VERSION ""

NS_ :

BS_:

BU_: AMS RES MCU DBU SWU ECU CCU DCU VMUF VMUR EBS IMU XBB CTMD DL

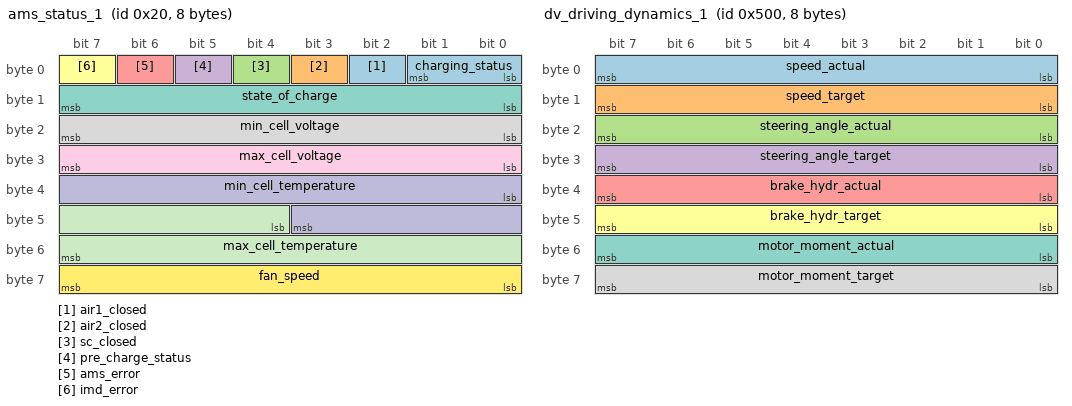
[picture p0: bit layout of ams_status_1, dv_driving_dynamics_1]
BO_ 32 ams_status_1: 8 AMS
 SG_ air1_closed : 2|1@1+ (1,0) [0|0] "" Vector__XXX
 SG_ air2_closed : 3|1@1+ (1,0) [0|0] "" Vector__XXX
 SG_ sc_closed : 4|1@1+ (1,0) [0|0] "" Vector__XXX
 SG_ pre_charge_status : 5|1@1+ (1,0) [0|0] "" Vector__XXX
 SG_ ams_error : 6|1@1+ (1,0) [0|0] "" Vector__XXX
 SG_ imd_error : 7|1@1+ (1,0) [0|0] "" Vector__XXX
 SG_ state_of_charge : 8|8@1+ (1,0) [0|100] "%" Vector__XXX
 SG_ min_cell_voltage : 16|8@1+ (0.00784,2.5) [2.5|4.5] "V" Vector__XXX
 SG_ max_cell_voltage : 24|8@1+ (0.00784,2.5) [2.5|4.5] "V" Vector__XXX
 SG_ min_cell_temperature : 32|12@1- (0.04884,-10) [-10|190] "C" Vector__XXX
 SG_ max_cell_temperature : 44|12@1- (0.04884,-10) [-10|190] "C" Vector__XXX
 SG_ fan_speed : 56|8@1+ (1,0) [0|100] "%" Vector__XXX
 SG_ charging_status : 0|2@1+ (1,0) [0|0] "" Vector__XXX

BO_ 1280 dv_driving_dynamics_1: 8 MCU
 SG_ speed_actual : 0|8@1+ (1,0) [0|0] "kmh" Vector__XXX
 SG_ speed_target : 8|8@1+ (1,0) [0|0] "kmh" Vector__XXX
 SG_ steering_angle_actual : 16|8@1- (0.5,0) [0|0] "degree" Vector__XXX
 SG_ steering_angle_target : 24|8@1- (0.5,0) [0|0] "degree" Vector__XXX
 SG_ brake_hydr_actual : 32|8@1+ (1,0) [0|0] "%" Vector__XXX
 SG_ brake_hydr_target : 40|8@1+ (1,0) [0|0] "%" Vector__XXX
 SG_ motor_moment_actual : 48|8@1- (1,0) [0|0] "%" Vector__XXX
 SG_ motor_moment_target : 56|8@1- (1,0) [0|0] "%" Vector__XXX

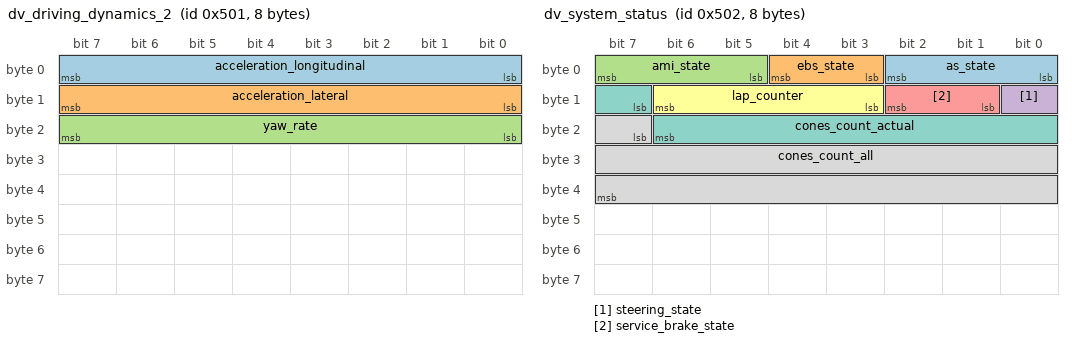
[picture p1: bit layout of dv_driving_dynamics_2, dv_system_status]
BO_ 1281 dv_driving_dynamics_2: 8 MCU
 SG_ acceleration_longitudinal : 0|8@1- (0.001953125,0) [0|0] "mps2" Vector__XXX
 SG_ acceleration_lateral : 8|8@1- (0.001953125,0) [0|0] "mps2" Vector__XXX
 SG_ yaw_rate : 16|8@1- (0.00195312,0) [0|0] "degree/s" Vector__XXX

BO_ 1282 dv_system_status: 8 MCU
 SG_ as_state : 0|3@1+ (1,0) [0|0] "" Vector__XXX
 SG_ ebs_state : 3|2@1+ (1,0) [0|0] "" Vector__XXX
 SG_ ami_state : 5|3@1+ (1,0) [0|0] "" Vector__XXX
 SG_ steering_state : 8|1@1+ (1,0) [0|0] "" Vector__XXX
 SG_ service_brake_state : 9|2@1+ (1,0) [0|0] "" Vector__XXX
 SG_ lap_counter : 11|4@1+ (1,0) [0|0] "" Vector__XXX
 SG_ cones_count_actual : 15|8@1+ (1,0) [0|0] "" Vector__XXX
 SG_ cones_count_all : 23|17@1+ (1,0) [0|0] "" Vector__XXX

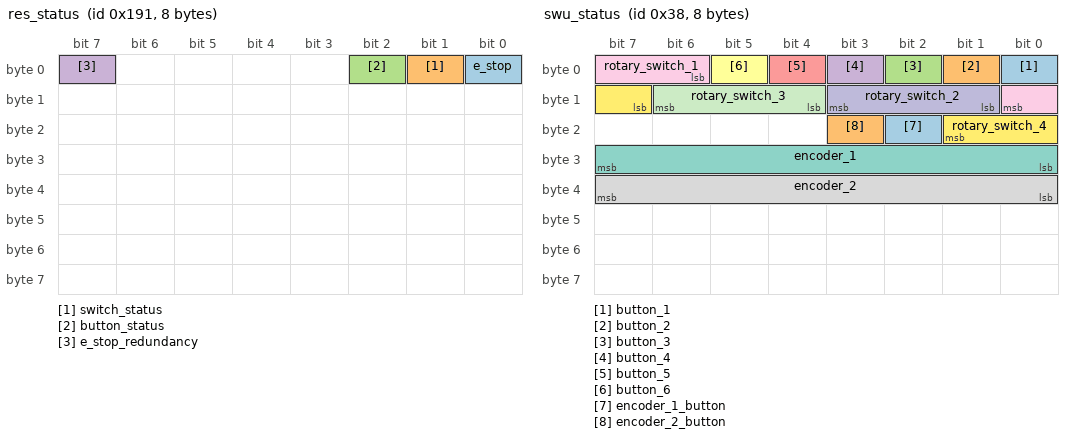
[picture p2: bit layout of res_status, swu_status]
BO_ 401 res_status: 8 RES
 SG_ e_stop : 0|1@1+ (1,0) [0|0] "" Vector__XXX
 SG_ switch_status : 1|1@1+ (1,0) [0|0] "" Vector__XXX
 SG_ button_status : 2|1@1+ (1,0) [0|0] "" Vector__XXX
 SG_ e_stop_redundancy : 7|1@1+ (1,0) [0|0] "" Vector__XXX

BO_ 1809 res_initialization: 8 MCU
 SG_ res_init : 0|8@1+ (1,0) [0|0] "" Vector__XXX

BO_ 0 res_ntm_node_control: 8 MCU
 SG_ requested_state : 0|8@1+ (1,0) [0|0] "" Vector__XXX
 SG_ node_id : 8|8@1+ (1,0) [0|0] "" Vector__XXX

BO_ 56 swu_status: 8 SWU
 SG_ button_1 : 0|1@1+ (1,0) [0|0] "" Vector__XXX
 SG_ button_2 : 1|1@1+ (1,0) [0|0] "" Vector__XXX
 SG_ button_3 : 2|1@1+ (1,0) [0|0] "" Vector__XXX
 SG_ button_4 : 3|1@1+ (1,0) [0|0] "" Vector__XXX
 SG_ button_5 : 4|1@1+ (1,0) [0|0] "" Vector__XXX
 SG_ button_6 : 5|1@1+ (1,0) [0|0] "" Vector__XXX
 SG_ encoder_1 : 24|8@1- (1,0) [-128|127] "" Vector__XXX
 SG_ encoder_2 : 32|8@1- (1,0) [-128|127] "" Vector__XXX
 SG_ rotary_switch_1 : 6|3@1+ (1,0) [0|7] "" Vector__XXX
 SG_ rotary_switch_2 : 9|3@1+ (1,0) [0|7] "" Vector__XXX
 SG_ rotary_switch_3 : 12|3@1+ (1,0) [0|7] "" Vector__XXX
 SG_ rotary_switch_4 : 15|3@1+ (1,0) [0|7] "" Vector__XXX
 SG_ encoder_1_button : 18|1@1+ (1,0) [0|0] "" Vector__XXX
 SG_ encoder_2_button : 19|1@1+ (1,0) [0|0] "" Vector__XXX

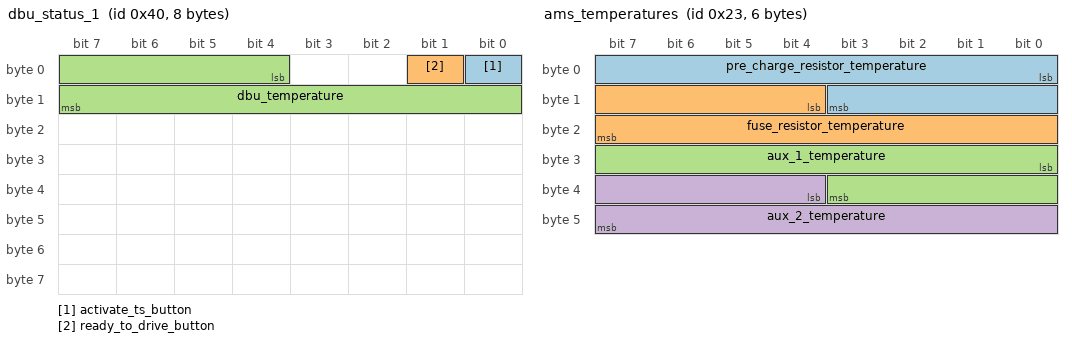
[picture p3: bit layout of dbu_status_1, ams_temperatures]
BO_ 64 dbu_status_1: 8 DBU
 SG_ activate_ts_button : 0|1@1+ (1,0) [0|0] "" AMS
 SG_ ready_to_drive_button : 1|1@1+ (1,0) [0|0] "" CCU
 SG_ dbu_temperature : 4|12@1- (0.04884,-10) [-10|190] "C" Vector__XXX

BO_ 35 ams_temperatures: 6 AMS
 SG_ pre_charge_resistor_temperature : 0|12@1- (0.04884,-10) [-10|190] "C" Vector__XXX
 SG_ fuse_resistor_temperature : 12|12@1- (0.04884,-10) [-10|190] "C" Vector__XXX
 SG_ aux_1_temperature : 24|12@1- (0.04884,-10) [-10|190] "C" Vector__XXX
 SG_ aux_2_temperature : 36|12@1- (0.04884,-10) [-10|190] "C" Vector__XXX

BO_ 33 ams_cell_voltages: 7 AMS
 SG_ voltage_multiplexor M : 0|8@1+ (1,0) [0|0] "" Vector__XXX
 SG_ v1s1 m0 : 8|8@1+ (0.00784,2.5) [2.5|4.5] "V" Vector__XXX
 SG_ v2s1 m0 : 16|8@1+ (0.00784,2.5) [2.5|4.5] "V" Vector__XXX
 SG_ v3s1 m0 : 24|8@1+ (0.00784,2.5) [2.5|4.5] "V" Vector__XXX
 SG_ v4s1 m0 : 32|8@1+ (0.00784,2.5) [2.5|4.5] "V" Vector__XXX
 SG_ v5s1 m0 : 40|8@1+ (0.00784,2.5) [2.5|4.5] "V" Vector__XXX
 SG_ v6s1 m0 : 48|8@1+ (0.00784,2.5) [2.5|4.5] "V" Vector__XXX
 SG_ v7s1 m1 : 8|8@1+ (0.00784,2.5) [2.5|4.5] "V" Vector__XXX
 SG_ v8s1 m1 : 16|8@1+ (0.00784,2.5) [2.5|4.5] "V" Vector__XXX
 SG_ v9s1 m1 : 24|8@1+ (0.00784,2.5) [2.5|4.5] "V" Vector__XXX
 SG_ v10s1 m1 : 32|8@1+ (0.00784,2.5) [2.5|4.5] "V" Vector__XXX
 SG_ v11s1 m1 : 40|8@1+ (0.00784,2.5) [2.5|4.5] "V" Vector__XXX
 SG_ v1s2 m2 : 8|8@1+ (0.00784,2.5) [2.5|4.5] "V" Vector__XXX
 SG_ v2s2 m2 : 16|8@1+ (0.00784,2.5) [2.5|4.5] "V" Vector__XXX
 SG_ v3s2 m2 : 24|8@1+ (0.00784,2.5) [2.5|4.5] "V" Vector__XXX
 SG_ v4s2 m2 : 32|8@1+ (0.00784,2.5) [2.5|4.5] "V" Vector__XXX
 SG_ v5s2 m2 : 40|8@1+ (0.00784,2.5) [2.5|4.5] "V" Vector__XXX
 SG_ v6s2 m2 : 48|8@1+ (0.00784,2.5) [2.5|4.5] "V" Vector__XXX
 SG_ v7s2 m3 : 8|8@1+ (0.00784,2.5) [2.5|4.5] "V" Vector__XXX
 SG_ v8s2 m3 : 16|8@1+ (0.00784,2.5) [2.5|4.5] "V" Vector__XXX
 SG_ v9s2 m3 : 24|8@1+ (0.00784,2.5) [2.5|4.5] "V" Vector__XXX
 SG_ v10s2 m3 : 32|8@1+ (0.00784,2.5) [2.5|4.5] "V" Vector__XXX
 SG_ v1s3 m4 : 8|8@1+ (0.00784,2.5) [2.5|4.5] "V" Vector__XXX
 SG_ v2s3 m4 : 16|8@1+ (0.00784,2.5) [2.5|4.5] "V" Vector__XXX
 SG_ v3s3 m4 : 24|8@1+ (0.00784,2.5) [2.5|4.5] "V" Vector__XXX
 SG_ v4s3 m4 : 32|8@1+ (0.00784,2.5) [2.5|4.5] "V" Vector__XXX
 SG_ v5s3 m4 : 40|8@1+ (0.00784,2.5) [2.5|4.5] "V" Vector__XXX
 SG_ v6s3 m4 : 48|8@1+ (0.00784,2.5) [2.5|4.5] "V" Vector__XXX
 SG_ v7s3 m5 : 8|8@1+ (0.00784,2.5) [2.5|4.5] "V" Vector__XXX
 SG_ v8s3 m5 : 16|8@1+ (0.00784,2.5) [2.5|4.5] "V" Vector__XXX
 SG_ v9s3 m5 : 24|8@1+ (0.00784,2.5) [2.5|4.5] "V" Vector__XXX
 SG_ v10s3 m5 : 32|8@1+ (0.00784,2.5) [2.5|4.5] "V" Vector__XXX
 SG_ v11s3 m5 : 40|8@1+ (0.00784,2.5) [2.5|4.5] "V" Vector__XXX
 SG_ v1s4 m6 : 8|8@1+ (0.00784,2.5) [2.5|4.5] "V" Vector__XXX
 SG_ v2s4 m6 : 16|8@1+ (0.00784,2.5) [2.5|4.5] "V" Vector__XXX
 SG_ v3s4 m6 : 24|8@1+ (0.00784,2.5) [2.5|4.5] "V" Vector__XXX
 SG_ v4s4 m6 : 32|8@1+ (0.00784,2.5) [2.5|4.5] "V" Vector__XXX
 SG_ v5s4 m6 : 40|8@1+ (0.00784,2.5) [2.5|4.5] "V" Vector__XXX
 SG_ v6s4 m6 : 48|8@1+ (0.00784,2.5) [2.5|4.5] "V" Vector__XXX
 SG_ v7s4 m7 : 8|8@1+ (0.00784,2.5) [2.5|4.5] "V" Vector__XXX
 SG_ v8s4 m7 : 16|8@1+ (0.00784,2.5) [2.5|4.5] "V" Vector__XXX
 SG_ v9s4 m7 : 24|8@1+ (0.00784,2.5) [2.5|4.5] "V" Vector__XXX
 SG_ v10s4 m7 : 32|8@1+ (0.00784,2.5) [2.5|4.5] "V" Vector__XXX
 SG_ v1s5 m8 : 8|8@1+ (0.00784,2.5) [2.5|4.5] "V" Vector__XXX
 SG_ v2s5 m8 : 16|8@1+ (0.00784,2.5) [2.5|4.5] "V" Vector__XXX
 SG_ v3s5 m8 : 24|8@1+ (0.00784,2.5) [2.5|4.5] "V" Vector__XXX
 SG_ v4s5 m8 : 32|8@1+ (0.00784,2.5) [2.5|4.5] "V" Vector__XXX
 SG_ v5s5 m8 : 40|8@1+ (0.00784,2.5) [2.5|4.5] "V" Vector__XXX
 SG_ v6s5 m8 : 48|8@1+ (0.00784,2.5) [2.5|4.5] "V" Vector__XXX
 SG_ v7s5 m9 : 8|8@1+ (0.00784,2.5) [2.5|4.5] "V" Vector__XXX
 SG_ v8s5 m9 : 16|8@1+ (0.00784,2.5) [2.5|4.5] "V" Vector__XXX
 SG_ v9s5 m9 : 24|8@1+ (0.00784,2.5) [2.5|4.5] "V" Vector__XXX
 SG_ v10s5 m9 : 32|8@1+ (0.00784,2.5) [2.5|4.5] "V" Vector__XXX
 SG_ v11s5 m9 : 40|8@1+ (0.00784,2.5) [2.5|4.5] "V" Vector__XXX
 SG_ v1s6 m10 : 8|8@1+ (0.00784,2.5) [2.5|4.5] "V" Vector__XXX
 SG_ v2s6 m10 : 16|8@1+ (0.00784,2.5) [2.5|4.5] "V" Vector__XXX
 SG_ v3s6 m10 : 24|8@1+ (0.00784,2.5) [2.5|4.5] "V" Vector__XXX
 SG_ v4s6 m10 : 32|8@1+ (0.00784,2.5) [2.5|4.5] "V" Vector__XXX
 SG_ v5s6 m10 : 40|8@1+ (0.00784,2.5) [2.5|4.5] "V" Vector__XXX
 SG_ v6s6 m10 : 48|8@1+ (0.00784,2.5) [2.5|4.5] "V" Vector__XXX
 SG_ v7s6 m11 : 8|8@1+ (0.00784,2.5) [2.5|4.5] "V" Vector__XXX
 SG_ v8s6 m11 : 16|8@1+ (0.00784,2.5) [2.5|4.5] "V" Vector__XXX
 SG_ v9s6 m11 : 24|8@1+ (0.00784,2.5) [2.5|4.5] "V" Vector__XXX
 SG_ v10s6 m11 : 32|8@1+ (0.00784,2.5) [2.5|4.5] "V" Vector__XXX
 SG_ v1s7 m12 : 8|8@1+ (0.00784,2.5) [2.5|4.5] "V" Vector__XXX
 SG_ v2s7 m12 : 16|8@1+ (0.00784,2.5) [2.5|4.5] "V" Vector__XXX
 SG_ v3s7 m12 : 24|8@1+ (0.00784,2.5) [2.5|4.5] "V" Vector__XXX
 SG_ v4s7 m12 : 32|8@1+ (0.00784,2.5) [2.5|4.5] "V" Vector__XXX
 SG_ v5s7 m12 : 40|8@1+ (0.00784,2.5) [2.5|4.5] "V" Vector__XXX
 SG_ v6s7 m12 : 48|8@1+ (0.00784,2.5) [2.5|4.5] "V" Vector__XXX
 SG_ v7s7 m13 : 8|8@1+ (0.00784,2.5) [2.5|4.5] "V" Vector__XXX
 SG_ v8s7 m13 : 16|8@1+ (0.00784,2.5) [2.5|4.5] "V" Vector__XXX
 SG_ v9s7 m13 : 24|8@1+ (0.00784,2.5) [2.5|4.5] "V" Vector__XXX
 SG_ v10s7 m13 : 32|8@1+ (0.00784,2.5) [2.5|4.5] "V" Vector__XXX
 SG_ v11s7 m13 : 40|8@1+ (0.00784,2.5) [2.5|4.5] "V" Vector__XXX
 SG_ v1s8 m14 : 8|8@1+ (0.00784,2.5) [2.5|4.5] "V" Vector__XXX
 SG_ v2s8 m14 : 16|8@1+ (0.00784,2.5) [2.5|4.5] "V" Vector__XXX
 SG_ v3s8 m14 : 24|8@1+ (0.00784,2.5) [2.5|4.5] "V" Vector__XXX
 SG_ v4s8 m14 : 32|8@1+ (0.00784,2.5) [2.5|4.5] "V" Vector__XXX
 SG_ v5s8 m14 : 40|8@1+ (0.00784,2.5) [2.5|4.5] "V" Vector__XXX
 SG_ v6s8 m14 : 48|8@1+ (0.00784,2.5) [2.5|4.5] "V" Vector__XXX
 SG_ v7s8 m15 : 8|8@1+ (0.00784,2.5) [2.5|4.5] "V" Vector__XXX
 SG_ v8s8 m15 : 16|8@1+ (0.00784,2.5) [2.5|4.5] "V" Vector__XXX
 SG_ v9s8 m15 : 24|8@1+ (0.00784,2.5) [2.5|4.5] "V" Vector__XXX
 SG_ v10s8 m15 : 32|8@1+ (0.00784,2.5) [2.5|4.5] "V" Vector__XXX
 SG_ v1s9 m16 : 8|8@1+ (0.00784,2.5) [2.5|4.5] "V" Vector__XXX
 SG_ v2s9 m16 : 16|8@1+ (0.00784,2.5) [2.5|4.5] "V" Vector__XXX
 SG_ v3s9 m16 : 24|8@1+ (0.00784,2.5) [2.5|4.5] "V" Vector__XXX
 SG_ v4s9 m16 : 32|8@1+ (0.00784,2.5) [2.5|4.5] "V" Vector__XXX
 SG_ v5s9 m16 : 40|8@1+ (0.00784,2.5) [2.5|4.5] "V" Vector__XXX
 SG_ v6s9 m16 : 48|8@1+ (0.00784,2.5) [2.5|4.5] "V" Vector__XXX
 SG_ v7s9 m17 : 8|8@1+ (0.00784,2.5) [2.5|4.5] "V" Vector__XXX
 SG_ v8s9 m17 : 16|8@1+ (0.00784,2.5) [2.5|4.5] "V" Vector__XXX
 SG_ v9s9 m17 : 24|8@1+ (0.00784,2.5) [2.5|4.5] "V" Vector__XXX
 SG_ v10s9 m17 : 32|8@1+ (0.00784,2.5) [2.5|4.5] "V" Vector__XXX
 SG_ v11s9 m17 : 40|8@1+ (0.00784,2.5) [2.5|4.5] "V" Vector__XXX
 SG_ v1s10 m18 : 8|8@1+ (0.00784,2.5) [2.5|4.5] "V" Vector__XXX
 SG_ v2s10 m18 : 16|8@1+ (0.00784,2.5) [2.5|4.5] "V" Vector__XXX
 SG_ v3s10 m18 : 24|8@1+ (0.00784,2.5) [2.5|4.5] "V" Vector__XXX
 SG_ v4s10 m18 : 32|8@1+ (0.00784,2.5) [2.5|4.5] "V" Vector__XXX
 SG_ v5s10 m18 : 40|8@1+ (0.00784,2.5) [2.5|4.5] "V" Vector__XXX
 SG_ v6s10 m18 : 48|8@1+ (0.00784,2.5) [2.5|4.5] "V" Vector__XXX
 SG_ v7s10 m19 : 8|8@1+ (0.00784,2.5) [2.5|4.5] "V" Vector__XXX
 SG_ v8s10 m19 : 16|8@1+ (0.00784,2.5) [2.5|4.5] "V" Vector__XXX
 SG_ v9s10 m19 : 24|8@1+ (0.00784,2.5) [2.5|4.5] "V" Vector__XXX
 SG_ v10s10 m19 : 32|8@1+ (0.00784,2.5) [2.5|4.5] "V" Vector__XXX
 SG_ v1s11 m20 : 8|8@1+ (0.00784,2.5) [2.5|4.5] "V" Vector__XXX
 SG_ v2s11 m20 : 16|8@1+ (0.00784,2.5) [2.5|4.5] "V" Vector__XXX
 SG_ v3s11 m20 : 24|8@1+ (0.00784,2.5) [2.5|4.5] "V" Vector__XXX
 SG_ v4s11 m20 : 32|8@1+ (0.00784,2.5) [2.5|4.5] "V" Vector__XXX
 SG_ v5s11 m20 : 40|8@1+ (0.00784,2.5) [2.5|4.5] "V" Vector__XXX
 SG_ v6s11 m20 : 48|8@1+ (0.00784,2.5) [2.5|4.5] "V" Vector__XXX
 SG_ v7s11 m21 : 8|8@1+ (0.00784,2.5) [2.5|4.5] "V" Vector__XXX
 SG_ v8s11 m21 : 16|8@1+ (0.00784,2.5) [2.5|4.5] "V" Vector__XXX
 SG_ v9s11 m21 : 24|8@1+ (0.00784,2.5) [2.5|4.5] "V" Vector__XXX
 SG_ v10s11 m21 : 32|8@1+ (0.00784,2.5) [2.5|4.5] "V" Vector__XXX
 SG_ v11s11 m21 : 40|8@1+ (0.00784,2.5) [2.5|4.5] "V" Vector__XXX
 SG_ v1s12 m22 : 8|8@1+ (0.00784,2.5) [2.5|4.5] "V" Vector__XXX
 SG_ v2s12 m22 : 16|8@1+ (0.00784,2.5) [2.5|4.5] "V" Vector__XXX
 SG_ v3s12 m22 : 24|8@1+ (0.00784,2.5) [2.5|4.5] "V" Vector__XXX
 SG_ v4s12 m22 : 32|8@1+ (0.00784,2.5) [2.5|4.5] "V" Vector__XXX
 SG_ v5s12 m22 : 40|8@1+ (0.00784,2.5) [2.5|4.5] "V" Vector__XXX
 SG_ v6s12 m22 : 48|8@1+ (0.00784,2.5) [2.5|4.5] "V" Vector__XXX
 SG_ v7s12 m23 : 8|8@1+ (0.00784,2.5) [2.5|4.5] "V" Vector__XXX
 SG_ v8s12 m23 : 16|8@1+ (0.00784,2.5) [2.5|4.5] "V" Vector__XXX
 SG_ v9s12 m23 : 24|8@1+ (0.00784,2.5) [2.5|4.5] "V" Vector__XXX
 SG_ v10s12 m23 : 32|8@1+ (0.00784,2.5) [2.5|4.5] "V" Vector__XXX

BO_ 34 ams_cell_temperatures: 8 AMS
 SG_ temperature_multiplexor M : 0|4@1+ (1,0) [0|0] "" Vector__XXX
 SG_ t1s1 m0 : 4|12@1- (0.04884,-10) [-10|190] "C" Vector__XXX
 SG_ t2s1 m0 : 16|12@1- (0.04884,-10) [-10|190] "C" Vector__XXX
 SG_ t3s1 m0 : 28|12@1- (0.04884,-10) [-10|190] "C" Vector__XXX
 SG_ t4s1 m0 : 40|12@1- (0.04884,-10) [-10|190] "C" Vector__XXX
 SG_ t5s1 m0 : 52|12@1- (0.04884,-10) [-10|190] "C" Vector__XXX
 SG_ t1s2 m1 : 4|12@1- (0.04884,-10) [-10|190] "C" Vector__XXX
 SG_ t2s2 m1 : 16|12@1- (0.04884,-10) [-10|190] "C" Vector__XXX
 SG_ t3s2 m1 : 28|12@1- (0.04884,-10) [-10|190] "C" Vector__XXX
 SG_ t4s2 m1 : 40|12@1- (0.04884,-10) [-10|190] "C" Vector__XXX
 SG_ t5s2 m1 : 52|12@1- (0.04884,-10) [-10|190] "C" Vector__XXX
 SG_ t1s3 m2 : 4|12@1- (0.04884,-10) [-10|190] "C" Vector__XXX
 SG_ t2s3 m2 : 16|12@1- (0.04884,-10) [-10|190] "C" Vector__XXX
 SG_ t3s3 m2 : 28|12@1- (0.04884,-10) [-10|190] "C" Vector__XXX
 SG_ t4s3 m2 : 40|12@1- (0.04884,-10) [-10|190] "C" Vector__XXX
 SG_ t5s3 m2 : 52|12@1- (0.04884,-10) [-10|190] "C" Vector__XXX
 SG_ t1s4 m3 : 4|12@1- (0.04884,-10) [-10|190] "C" Vector__XXX
 SG_ t2s4 m3 : 16|12@1- (0.04884,-10) [-10|190] "C" Vector__XXX
 SG_ t3s4 m3 : 28|12@1- (0.04884,-10) [-10|190] "C" Vector__XXX
 SG_ t4s4 m3 : 40|12@1- (0.04884,-10) [-10|190] "C" Vector__XXX
 SG_ t5s4 m3 : 52|12@1- (0.04884,-10) [-10|190] "C" Vector__XXX
 SG_ t1s5 m4 : 4|12@1- (0.04884,-10) [-10|190] "C" Vector__XXX
 SG_ t2s5 m4 : 16|12@1- (0.04884,-10) [-10|190] "C" Vector__XXX
 SG_ t3s5 m4 : 28|12@1- (0.04884,-10) [-10|190] "C" Vector__XXX
 SG_ t4s5 m4 : 40|12@1- (0.04884,-10) [-10|190] "C" Vector__XXX
 SG_ t5s5 m4 : 52|12@1- (0.04884,-10) [-10|190] "C" Vector__XXX
 SG_ t1s6 m5 : 4|12@1- (0.04884,-10) [-10|190] "C" Vector__XXX
 SG_ t2s6 m5 : 16|12@1- (0.04884,-10) [-10|190] "C" Vector__XXX
 SG_ t3s6 m5 : 28|12@1- (0.04884,-10) [-10|190] "C" Vector__XXX
 SG_ t4s6 m5 : 40|12@1- (0.04884,-10) [-10|190] "C" Vector__XXX
 SG_ t5s6 m5 : 52|12@1- (0.04884,-10) [-10|190] "C" Vector__XXX
 SG_ t1s7 m6 : 4|12@1- (0.04884,-10) [-10|190] "C" Vector__XXX
 SG_ t2s7 m6 : 16|12@1- (0.04884,-10) [-10|190] "C" Vector__XXX
 SG_ t3s7 m6 : 28|12@1- (0.04884,-10) [-10|190] "C" Vector__XXX
 SG_ t4s7 m6 : 40|12@1- (0.04884,-10) [-10|190] "C" Vector__XXX
 SG_ t5s7 m6 : 52|12@1- (0.04884,-10) [-10|190] "C" Vector__XXX
 SG_ t1s8 m7 : 4|12@1- (0.04884,-10) [-10|190] "C" Vector__XXX
 SG_ t2s8 m7 : 16|12@1- (0.04884,-10) [-10|190] "C" Vector__XXX
 SG_ t3s8 m7 : 28|12@1- (0.04884,-10) [-10|190] "C" Vector__XXX
 SG_ t4s8 m7 : 40|12@1- (0.04884,-10) [-10|190] "C" Vector__XXX
 SG_ t5s8 m7 : 52|12@1- (0.04884,-10) [-10|190] "C" Vector__XXX
 SG_ t1s9 m8 : 4|12@1- (0.04884,-10) [-10|190] "C" Vector__XXX
 SG_ t2s9 m8 : 16|12@1- (0.04884,-10) [-10|190] "C" Vector__XXX
 SG_ t3s9 m8 : 28|12@1- (0.04884,-10) [-10|190] "C" Vector__XXX
 SG_ t4s9 m8 : 40|12@1- (0.04884,-10) [-10|190] "C" Vector__XXX
 SG_ t5s9 m8 : 52|12@1- (0.04884,-10) [-10|190] "C" Vector__XXX
 SG_ t1s10 m9 : 4|12@1- (0.04884,-10) [-10|190] "C" Vector__XXX
 SG_ t2s10 m9 : 16|12@1- (0.04884,-10) [-10|190] "C" Vector__XXX
 SG_ t3s10 m9 : 28|12@1- (0.04884,-10) [-10|190] "C" Vector__XXX
 SG_ t4s10 m9 : 40|12@1- (0.04884,-10) [-10|190] "C" Vector__XXX
 SG_ t5s10 m9 : 52|12@1- (0.04884,-10) [-10|190] "C" Vector__XXX
 SG_ t1s11 m10 : 4|12@1- (0.04884,-10) [-10|190] "C" Vector__XXX
 SG_ t2s11 m10 : 16|12@1- (0.04884,-10) [-10|190] "C" Vector__XXX
 SG_ t3s11 m10 : 28|12@1- (0.04884,-10) [-10|190] "C" Vector__XXX
 SG_ t4s11 m10 : 40|12@1- (0.04884,-10) [-10|190] "C" Vector__XXX
 SG_ t5s11 m10 : 52|12@1- (0.04884,-10) [-10|190] "C" Vector__XXX
 SG_ t1s12 m11 : 4|12@1- (0.04884,-10) [-10|190] "C" Vector__XXX
 SG_ t2s12 m11 : 16|12@1- (0.04884,-10) [-10|190] "C" Vector__XXX
 SG_ t3s12 m11 : 28|12@1- (0.04884,-10) [-10|190] "C" Vector__XXX
 SG_ t4s12 m11 : 40|12@1- (0.04884,-10) [-10|190] "C" Vector__XXX
 SG_ t5s12 m11 : 52|12@1- (0.04884,-10) [-10|190] "C" Vector__XXX

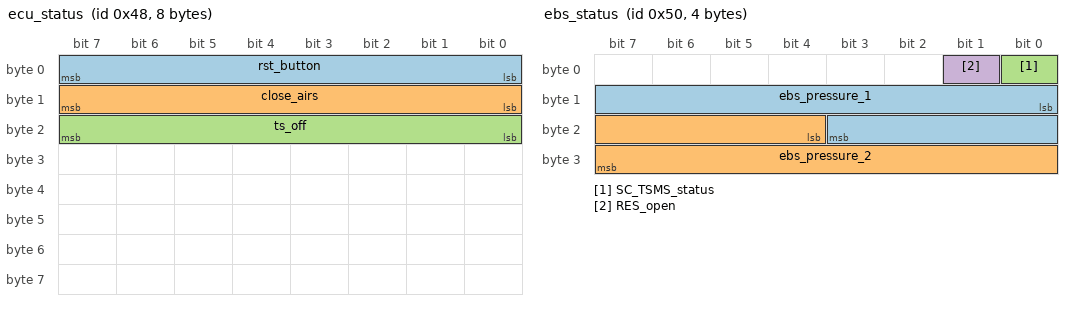
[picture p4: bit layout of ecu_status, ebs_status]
BO_ 72 ecu_status: 8 ECU
 SG_ rst_button : 0|8@1+ (1,0) [0|0] "" Vector__XXX
 SG_ close_airs : 8|8@1+ (1,0) [0|0] "" Vector__XXX
 SG_ ts_off : 16|8@1+ (1,0) [0|0] "" Vector__XXX

BO_ 80 ebs_status: 4 EBS
 SG_ ebs_pressure_1 : 8|12@1+ (1,0) [0|0] "" Vector__XXX
 SG_ ebs_pressure_2 : 20|12@1+ (1,0) [0|0] "" Vector__XXX
 SG_ SC_TSMS_status : 0|1@1+ (1,0) [0|0] "" Vector__XXX
 SG_ RES_open : 1|1@1+ (1,0) [0|0] "" Vector__XXX

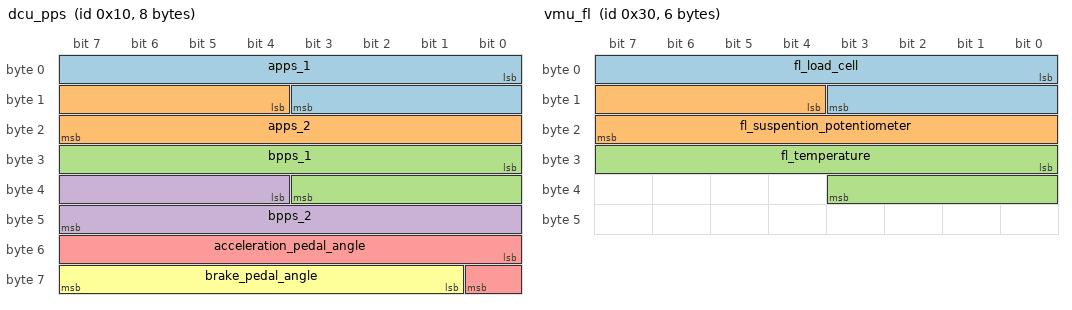
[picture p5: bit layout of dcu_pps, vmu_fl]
BO_ 16 dcu_pps: 8 DCU
 SG_ apps_1 : 0|12@1+ (1,0) [0|0] "" Vector__XXX
 SG_ apps_2 : 12|12@1+ (1,0) [0|0] "" Vector__XXX
 SG_ bpps_1 : 24|12@1+ (1,0) [0|0] "" Vector__XXX
 SG_ bpps_2 : 36|12@1+ (1,0) [0|0] "" Vector__XXX
 SG_ acceleration_pedal_angle : 48|9@1+ (1,0) [0|51.2] "deg" Vector__XXX
 SG_ brake_pedal_angle : 57|7@1+ (10,0) [0|12.8] "deg" Vector__XXX

BO_ 48 vmu_fl: 6 VMUF
 SG_ fl_load_cell : 0|12@1- (1,0) [0|0] "" Vector__XXX
 SG_ fl_suspention_potentiometer : 12|12@1- (1,0) [0|0] "" Vector__XXX
 SG_ fl_temperature : 24|12@1+ (0.04884,-10) [-10|190] "C" Vector__XXX

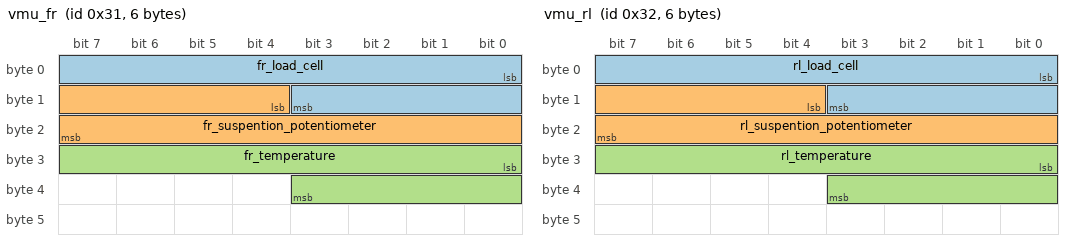
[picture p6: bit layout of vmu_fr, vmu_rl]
BO_ 49 vmu_fr: 6 VMUF
 SG_ fr_load_cell : 0|12@1- (1,0) [0|0] "" Vector__XXX
 SG_ fr_suspention_potentiometer : 12|12@1- (1,0) [0|0] "" Vector__XXX
 SG_ fr_temperature : 24|12@1+ (0.04884,-10) [-10|190] "C" Vector__XXX

BO_ 50 vmu_rl: 6 VMUR
 SG_ rl_load_cell : 0|12@1- (1,0) [0|0] "" Vector__XXX
 SG_ rl_suspention_potentiometer : 12|12@1- (1,0) [0|0] "" Vector__XXX
 SG_ rl_temperature : 24|12@1+ (0.04884,-10) [-10|190] "C" Vector__XXX

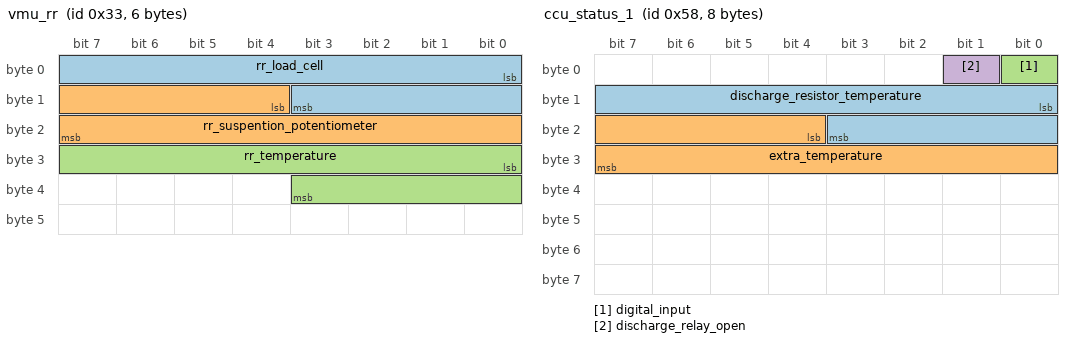
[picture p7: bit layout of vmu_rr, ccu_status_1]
BO_ 51 vmu_rr: 6 VMUR
 SG_ rr_load_cell : 0|12@1- (1,0) [0|0] "" Vector__XXX
 SG_ rr_suspention_potentiometer : 12|12@1- (1,0) [0|0] "" Vector__XXX
 SG_ rr_temperature : 24|12@1+ (0.04884,-10) [-10|190] "C" Vector__XXX

BO_ 89 ccu_status_2: 8 CCU
 SG_ fan1_speed m0 : 8|8@1+ (1,0) [0|100] "%" Vector__XXX
 SG_ fan2_speed m1 : 8|8@1+ (1,0) [0|100] "%" Vector__XXX
 SG_ fan3_speed m2 : 8|8@1+ (1,0) [0|100] "%" Vector__XXX
 SG_ fron_pump_speed m0 : 16|8@1+ (1,0) [0|100] "%" Vector__XXX
 SG_ rear_pump_speed m1 : 16|8@1+ (1,0) [0|100] "%" Vector__XXX
 SG_ inverter_pump_speed m2 : 16|8@1+ (1,0) [0|100] "%" Vector__XXX
 SG_ fron_coolant_temperature m0 : 24|12@1- (0.04884,-10) [-10|190] "C" Vector__XXX
 SG_ rear_coolant_temperature m1 : 24|12@1- (0.04884,-10) [-10|190] "C" Vector__XXX
 SG_ inverter_coolant_temperature m2 : 24|12@1- (0.04884,-10) [-10|190] "C" Vector__XXX
 SG_ mux_ID M : 0|8@1+ (1,0) [0|0] "" Vector__XXX

BO_ 88 ccu_status_1: 8 CCU
 SG_ discharge_resistor_temperature : 8|12@1+ (1,0) [-10|190] "C" Vector__XXX
 SG_ extra_temperature : 20|12@1+ (1,0) [-10|190] "C" Vector__XXX
 SG_ digital_input : 0|1@1+ (1,0) [-10|190] "C" Vector__XXX
 SG_ discharge_relay_open : 1|1@1+ (1,0) [-10|190] "C" Vector__XXX

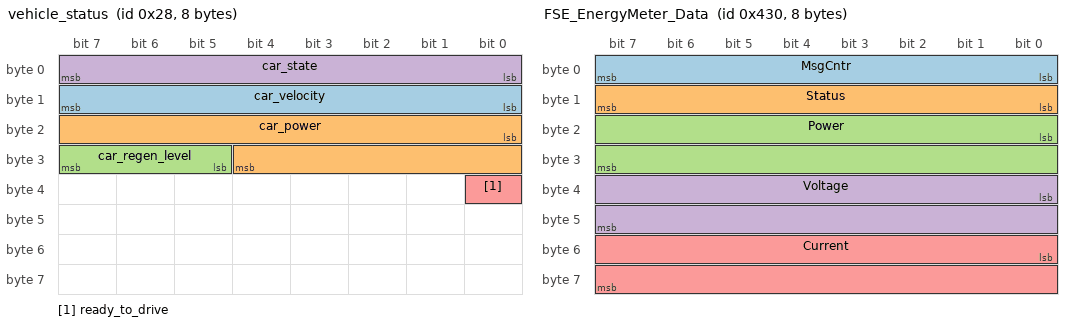
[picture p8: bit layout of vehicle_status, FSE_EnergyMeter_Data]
BO_ 40 vehicle_status: 8 MCU
 SG_ car_velocity : 8|8@1+ (1,0) [0|200] "kph" Vector__XXX
 SG_ car_power : 16|13@1+ (1,0) [0|8000] "W" Vector__XXX
 SG_ car_regen_level : 29|3@1+ (1,0) [0|0] "" Vector__XXX
 SG_ car_state : 0|8@1+ (1,0) [0|0] "" Vector__XXX
 SG_ ready_to_drive : 32|1@1+ (1,0) [0|0] "" Vector__XXX

BO_ 1072 FSE_EnergyMeter_Data: 8 DL
 SG_ MsgCntr : 0|8@1+ (1,0) [0|255] "" Vector__XXX
 SG_ Status : 8|8@1+ (1,0) [0|255] "" Vector__XXX
 SG_ Power : 16|16@1- (3,0) [-98304|98301] "W" Vector__XXX
 SG_ Voltage : 32|16@1- (0.04,0) [-1310.72|1310.68] "V" Vector__XXX
 SG_ Current : 48|16@1- (0.05,0) [-1638.4|1638.35] "A" Vector__XXX

BO_ 255 fault: 8 Vector__XXX
 SG_ unit_id M : 0|8@1+ (1,0) [0|0] "" Vector__XXX
 SG_ apps_discrepancy m4 : 8|1@1+ (1,0) [0|0] "" Vector__XXX
 SG_ bpps_discrepancy m4 : 9|1@1+ (1,0) [0|0] "" Vector__XXX
 SG_ sc_open m0 : 8|1@1+ (1,0) [0|0] "" Vector__XXX
 SG_ apps_out_of_range m4 : 12|1@1+ (1,0) [0|0] "" Vector__XXX
 SG_ bpps_out_of_range m4 : 13|1@1+ (1,0) [0|0] "" Vector__XXX
 SG_ brake_pressure_out_of_range m4 : 14|1@1+ (1,0) [0|0] "" Vector__XXX
 SG_ brake_pressure_discrepancy m4 : 10|1@1+ (1,0) [0|0] "" Vector__XXX
 SG_ steering_angle_discrepancy m0 : 11|1@1+ (1,0) [0|0] "" Vector__XXX
 SG_ steering_angle_out_of_range m4 : 15|1@1+ (1,0) [0|0] "" Vector__XXX
 SG_ ts_off_watchdog_triggered m3 : 8|1@1+ (1,0) [0|0] "" Vector__XXX

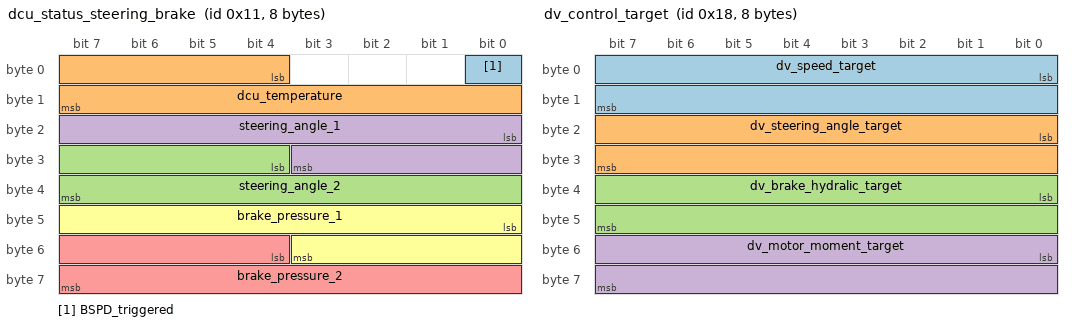
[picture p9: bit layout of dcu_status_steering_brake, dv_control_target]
BO_ 17 dcu_status_steering_brake: 8 DCU
 SG_ BSPD_triggered : 0|1@1+ (1,0) [0|0] "" Vector__XXX
 SG_ dcu_temperature : 4|12@1+ (1,0) [-10|190] "C" Vector__XXX
 SG_ steering_angle_2 : 28|12@1- (1,0) [0|0] "" Vector__XXX
 SG_ steering_angle_1 : 16|12@1- (1,0) [0|0] "" Vector__XXX
 SG_ brake_pressure_2 : 52|12@1+ (1,0) [0|0] "" Vector__XXX
 SG_ brake_pressure_1 : 40|12@1+ (1,0) [0|0] "" Vector__XXX

BO_ 65 dbu_status_2: 8 DBU
 SG_ screen_id : 0|8@1+ (1,0) [0|0] "" Vector__XXX

BO_ 24 dv_control_target: 8 XBB
 SG_ dv_speed_target : 0|16@1+ (1,0) [0|0] "kph" Vector__XXX
 SG_ dv_steering_angle_target : 16|16@1+ (1,0) [0|0] "degree" Vector__XXX
 SG_ dv_brake_hydralic_target : 32|16@1+ (1,0) [0|0] "%" Vector__XXX
 SG_ dv_motor_moment_target : 48|16@1+ (1,0) [0|0] "%" Vector__XXX

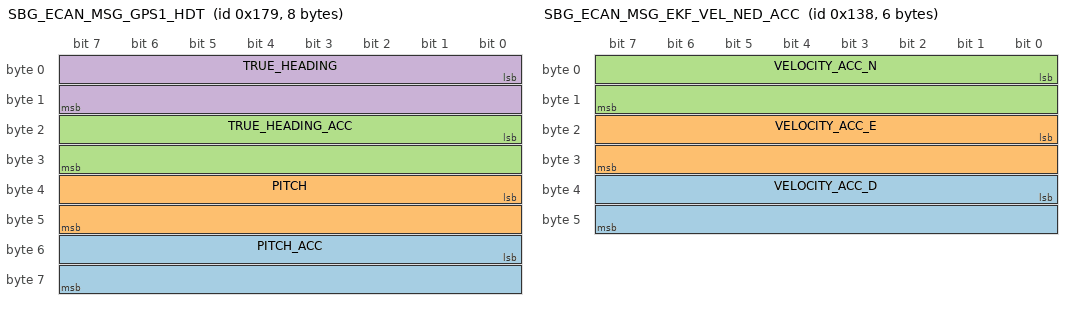
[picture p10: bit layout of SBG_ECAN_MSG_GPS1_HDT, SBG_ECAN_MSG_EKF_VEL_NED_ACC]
BO_ 377 SBG_ECAN_MSG_GPS1_HDT: 8 IMU
 SG_ PITCH_ACC : 48|16@1+ (0.01,0) [0|655.35] "°" Vector__XXX
 SG_ PITCH : 32|16@1- (0.01,0) [-327.68|327.67] "°" Vector__XXX
 SG_ TRUE_HEADING_ACC : 16|16@1+ (0.01,0) [0|655.35] "°" Vector__XXX
 SG_ TRUE_HEADING : 0|16@1+ (0.01,0) [0|655.35] "°" Vector__XXX

BO_ 376 SBG_ECAN_MSG_GPS1_HDT_INFO: 6 IMU
 SG_ STATUS : 32|16@1+ (1,0) [0|65535] "" Vector__XXX
 SG_ TIME_STAMP : 0|32@1+ (1,0) [0|2704] "µs" Vector__XXX

BO_ 353 SBG_ECAN_MSG_ODO_VEL: 2 IMU
 SG_ VELOCITY : 0|16@1- (0.01,0) [-327.68|327.67] "m.s-1" Vector__XXX

BO_ 312 SBG_ECAN_MSG_EKF_VEL_NED_ACC: 6 IMU
 SG_ VELOCITY_ACC_D : 32|16@1- (0.01,0) [-327.68|327.67] "m.s-1" Vector__XXX
 SG_ VELOCITY_ACC_E : 16|16@1- (0.01,0) [-327.68|327.67] "m.s-1" Vector__XXX
 SG_ VELOCITY_ACC_N : 0|16@1- (0.01,0) [-327.68|327.67] "m.s-1" Vector__XXX

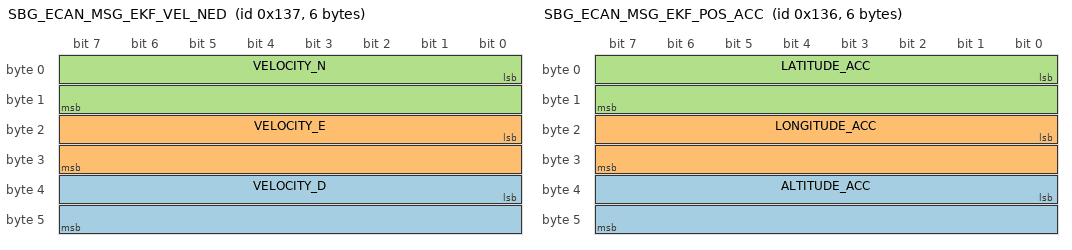
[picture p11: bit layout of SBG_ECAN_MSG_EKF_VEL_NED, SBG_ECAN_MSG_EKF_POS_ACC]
BO_ 311 SBG_ECAN_MSG_EKF_VEL_NED: 6 IMU
 SG_ VELOCITY_D : 32|16@1- (0.01,0) [-327.68|327.67] "m.s-1" Vector__XXX
 SG_ VELOCITY_E : 16|16@1- (0.01,0) [-327.68|327.67] "m.s-1" Vector__XXX
 SG_ VELOCITY_N : 0|16@1- (0.01,0) [-327.68|327.67] "m.s-1" Vector__XXX

BO_ 310 SBG_ECAN_MSG_EKF_POS_ACC: 6 IMU
 SG_ ALTITUDE_ACC : 32|16@1+ (0.01,0) [0|655.35] "m" Vector__XXX
 SG_ LONGITUDE_ACC : 16|16@1+ (0.01,0) [0|655.35] "m" Vector__XXX
 SG_ LATITUDE_ACC : 0|16@1+ (0.01,0) [0|655.35] "m" Vector__XXX

BO_ 308 SBG_ECAN_MSG_EKF_POS: 8 IMU
 SG_ LONGITUDE : 32|32@1- (1e-07,0) [-214.7483648|214.7483647] "°" Vector__XXX
 SG_ LATITUDE : 0|32@1- (1e-07,0) [-214.7483648|214.7483647] "°" Vector__XXX

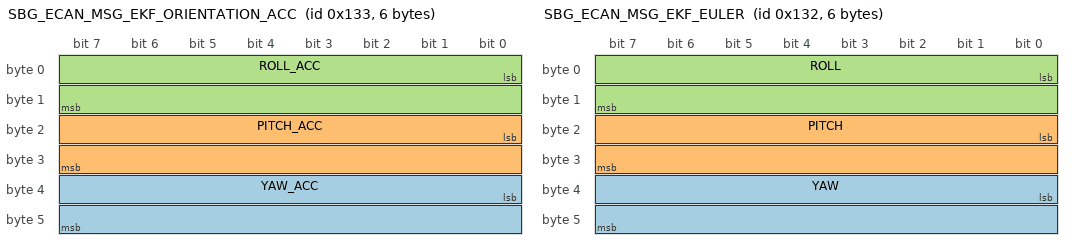
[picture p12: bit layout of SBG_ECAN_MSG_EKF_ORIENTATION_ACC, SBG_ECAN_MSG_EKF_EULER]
BO_ 307 SBG_ECAN_MSG_EKF_ORIENTATION_ACC: 6 IMU
 SG_ YAW_ACC : 32|16@1+ (0.0001,0) [0|6.5535] "rad" Vector__XXX
 SG_ PITCH_ACC : 16|16@1+ (0.0001,0) [0|6.5535] "rad" Vector__XXX
 SG_ ROLL_ACC : 0|16@1+ (0.0001,0) [0|6.5535] "rad" Vector__XXX

BO_ 306 SBG_ECAN_MSG_EKF_EULER: 6 IMU
 SG_ YAW : 32|16@1- (0.0001,0) [-3.2768|3.2767] "rad" Vector__XXX
 SG_ PITCH : 16|16@1- (0.0001,0) [-3.2768|3.2767] "rad" Vector__XXX
 SG_ ROLL : 0|16@1- (0.0001,0) [-3.2768|3.2767] "rad" Vector__XXX

BO_ 304 SBG_ECAN_MSG_EKF_INFO: 4 IMU
 SG_ TIME_STAMP : 0|32@1+ (1,0) [0|2704] "µs" Vector__XXX

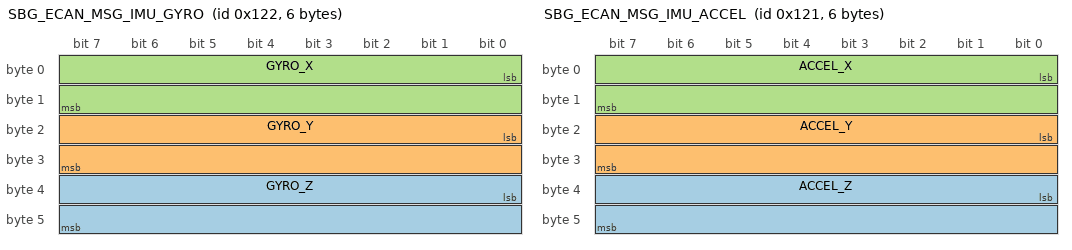
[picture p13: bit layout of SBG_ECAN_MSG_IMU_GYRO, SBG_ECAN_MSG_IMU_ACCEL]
BO_ 290 SBG_ECAN_MSG_IMU_GYRO: 6 IMU
 SG_ GYRO_Z : 32|16@1- (0.001,0) [-32.768|32.767] "rad.s-1" Vector__XXX
 SG_ GYRO_Y : 16|16@1- (0.001,0) [-32.768|32.767] "rad.s-1" Vector__XXX
 SG_ GYRO_X : 0|16@1- (0.001,0) [-32.768|32.767] "rad.s-1" Vector__XXX

BO_ 289 SBG_ECAN_MSG_IMU_ACCEL: 6 IMU
 SG_ ACCEL_Z : 32|16@1- (0.01,0) [-327.68|327.67] "m.s-2" Vector__XXX
 SG_ ACCEL_Y : 16|16@1- (0.01,0) [-327.68|327.67] "m.s-2" Vector__XXX
 SG_ ACCEL_X : 0|16@1- (0.01,0) [-327.68|327.67] "m.s-2" Vector__XXX

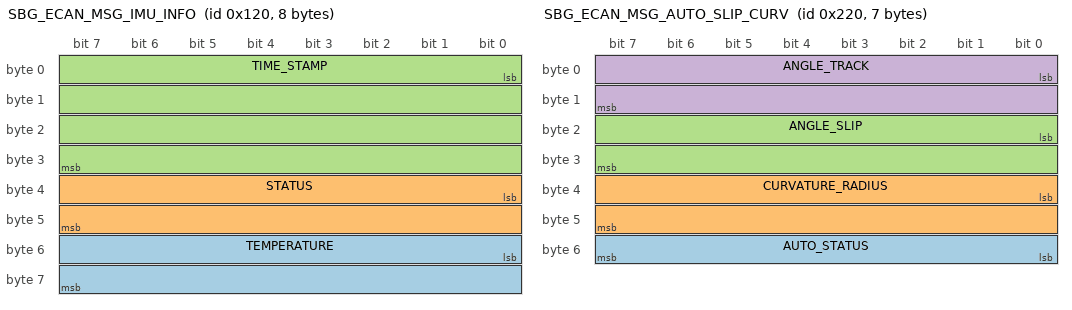
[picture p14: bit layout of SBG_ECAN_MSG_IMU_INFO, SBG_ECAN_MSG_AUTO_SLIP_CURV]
BO_ 288 SBG_ECAN_MSG_IMU_INFO: 8 IMU
 SG_ TEMPERATURE : 48|16@1- (0.01,0) [-327.68|327.67] "°C" Vector__XXX
 SG_ STATUS : 32|16@1+ (1,0) [0|65535] "" Vector__XXX
 SG_ TIME_STAMP : 0|32@1+ (1,0) [0|2704] "µs" Vector__XXX

BO_ 544 SBG_ECAN_MSG_AUTO_SLIP_CURV: 7 IMU
 SG_ AUTO_STATUS : 48|8@1+ (1,0) [0|255] "" Vector__XXX
 SG_ CURVATURE_RADIUS : 32|16@1+ (0.01,0) [0|655.35] "m" Vector__XXX
 SG_ ANGLE_SLIP : 16|16@1- (0.0001,0) [-3.2768|3.2767] "rad" Vector__XXX
 SG_ ANGLE_TRACK : 0|16@1- (0.0001,0) [-3.2768|3.2767] "rad" Vector__XXX

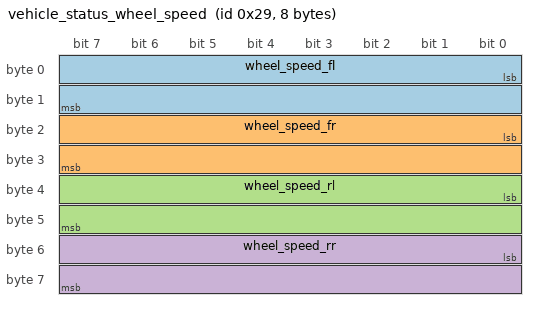
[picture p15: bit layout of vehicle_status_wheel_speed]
BO_ 41 vehicle_status_wheel_speed: 8 MCU
 SG_ wheel_speed_fl : 0|16@1- (1,0) [0|0] "rpm" Vector__XXX
 SG_ wheel_speed_fr : 16|16@1- (1,0) [0|0] "rpm" Vector__XXX
 SG_ wheel_speed_rl : 32|16@1- (1,0) [0|0] "rpm" Vector__XXX
 SG_ wheel_speed_rr : 48|16@1- (1,0) [0|0] "rpm" Vector__XXX

CM_ BU_ CTMD "Cell temperature monitor provided by FSG.";
CM_ BU_ DL "Data Logger provided by FSG";
CM_ BO_ 32 "Used for DBU hardware IO.";
CM_ BO_ 1280 "Required by FSG.";
CM_ BO_ 1281 "Required by FSG.";
CM_ BO_ 1282 "Required by FSG.";
CM_ BO_ 65 "Used for DBU software IO.";
VAL_ 32 air1_closed 0 "OPEN" 1 "CLOSED" ;
VAL_ 32 air2_closed 0 "OPEN" 1 "CLOSED" ;
VAL_ 32 sc_closed 0 "OPEN" 1 "CLOSED" ;
VAL_ 32 pre_charge_status 0 "NOT ACTIVE" 1 "ACTIVE" ;
VAL_ 32 ams_error 0 "OK" 1 "ERROR" ;
VAL_ 32 imd_error 0 "OK" 1 "ERROR" ;
VAL_ 32 charging_status 0 "IDLE" 1 "CHARGING" 2 "DISCHARGING" 3 "FULL" ;
VAL_ 1282 as_state 0 "OFF" 1 "READY" 2 "DRIVING" 3 "EMERGENCY_BRAKE" 4 "FINISH" ;
VAL_ 1282 ebs_state 0 "UNAVAILABLE" 1 "ARMED" 2 "ACTIVATED" ;
VAL_ 1282 ami_state 0 "ACCELERATION" 1 "SKIDPAD" 2 "TRACKDRIVE" 3 "BRAKETEST" 4 "INSPECTION" 5 "AUTOCROSS" 6 "MANUAL_DRIVNING" ;
VAL_ 1282 service_brake_state 0 "DISENGAGED" 1 "ENGAGED" 2 "AVAILABLE" ;
VAL_ 401 e_stop 0 "E-STOP OK" 1 "E-STOP ACTIVE" ;
VAL_ 401 switch_status 0 "LOW" 1 "HIGH" ;
VAL_ 401 button_status 0 "LOW" 1 "HIGH" ;
VAL_ 401 e_stop_redundancy 0 "E-STOP OK" 1 "E-STOP ACTIVE" ;
VAL_ 40 car_state 0 "car_off" ;

BA_DEF_ BO_  "GenMsgCycleTime" INT 0 65535;
BA_DEF_DEF_  "GenMsgCycleTime" 0;
BA_ "GenMsgCycleTime" BO_ 32 400;
BA_ "GenMsgCycleTime" BO_ 33 800;
BA_ "GenMsgCycleTime" BO_ 34 1200;
BA_ "GenMsgCycleTime" BO_ 35 1200;
